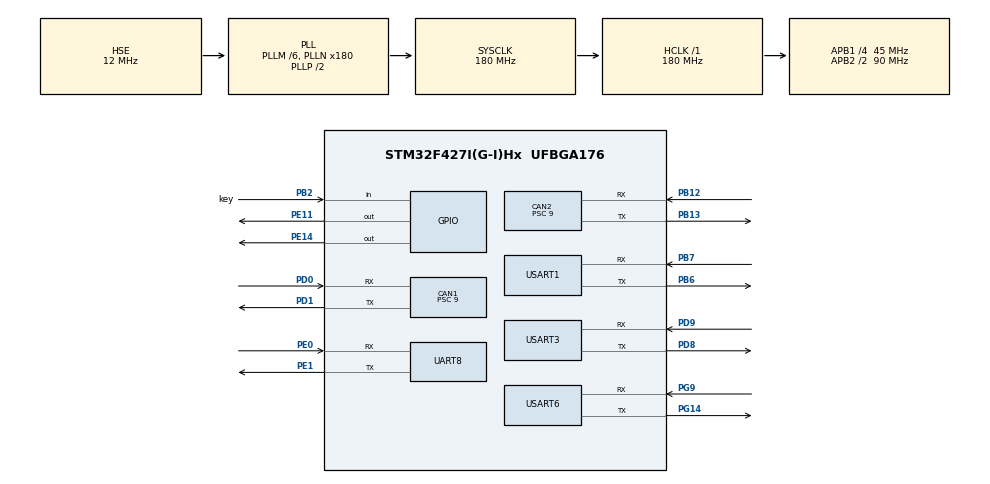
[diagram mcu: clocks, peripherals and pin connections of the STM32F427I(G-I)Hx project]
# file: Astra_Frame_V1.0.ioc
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CAN1.BS1=CAN_BS1_2TQ
CAN1.BS2=CAN_BS2_2TQ
CAN1.CalculateBaudRate=1000000
CAN1.CalculateTimeBit=1000
CAN1.CalculateTimeQuantum=200.0
CAN1.Prescaler=9
CAN2.BS1=CAN_BS1_2TQ
CAN2.BS2=CAN_BS2_2TQ
CAN2.CalculateBaudRate=1000000
CAN2.CalculateTimeBit=1000
CAN2.CalculateTimeQuantum=200.0
CAN2.Prescaler=9
Dma.Request0=USART1_RX
Dma.Request1=USART1_TX
Dma.Request2=USART3_RX
Dma.Request3=USART6_TX
Dma.Request4=USART6_RX
Dma.Request5=UART8_RX
Dma.Request6=UART8_TX
Dma.UART8_RX.5.Direction=DMA_PERIPH_TO_MEMORY
Dma.UART8_RX.5.FIFOMode=DMA_FIFOMODE_DISABLE
Dma.UART8_RX.5.Instance=DMA1_Stream6
Dma.UART8_RX.5.MemDataAlignment=DMA_MDATAALIGN_BYTE
Dma.UART8_RX.5.MemInc=DMA_MINC_ENABLE
Dma.UART8_RX.5.Mode=DMA_NORMAL
Dma.UART8_RX.5.PeriphDataAlignment=DMA_PDATAALIGN_BYTE
Dma.UART8_RX.5.PeriphInc=DMA_PINC_DISABLE
Dma.UART8_RX.5.Priority=DMA_PRIORITY_LOW
Dma.UART8_TX.6.Direction=DMA_MEMORY_TO_PERIPH
Dma.UART8_TX.6.FIFOMode=DMA_FIFOMODE_DISABLE
Dma.UART8_TX.6.Instance=DMA1_Stream0
Dma.UART8_TX.6.MemDataAlignment=DMA_MDATAALIGN_BYTE
Dma.UART8_TX.6.MemInc=DMA_MINC_ENABLE
Dma.UART8_TX.6.Mode=DMA_NORMAL
Dma.UART8_TX.6.PeriphDataAlignment=DMA_PDATAALIGN_BYTE
Dma.UART8_TX.6.PeriphInc=DMA_PINC_DISABLE
Dma.UART8_TX.6.Priority=DMA_PRIORITY_LOW
Dma.USART1_RX.0.Direction=DMA_PERIPH_TO_MEMORY
Dma.USART1_RX.0.FIFOMode=DMA_FIFOMODE_DISABLE
Dma.USART1_RX.0.Instance=DMA2_Stream2
Dma.USART1_RX.0.MemDataAlignment=DMA_MDATAALIGN_BYTE
Dma.USART1_RX.0.MemInc=DMA_MINC_ENABLE
Dma.USART1_RX.0.Mode=DMA_NORMAL
Dma.USART1_RX.0.PeriphDataAlignment=DMA_PDATAALIGN_BYTE
Dma.USART1_RX.0.PeriphInc=DMA_PINC_DISABLE
Dma.USART1_RX.0.Priority=DMA_PRIORITY_LOW
Dma.USART1_TX.1.Direction=DMA_MEMORY_TO_PERIPH
Dma.USART1_TX.1.FIFOMode=DMA_FIFOMODE_DISABLE
Dma.USART1_TX.1.Instance=DMA2_Stream7
Dma.USART1_TX.1.MemDataAlignment=DMA_MDATAALIGN_BYTE
Dma.USART1_TX.1.MemInc=DMA_MINC_ENABLE
Dma.USART1_TX.1.Mode=DMA_NORMAL
Dma.USART1_TX.1.PeriphDataAlignment=DMA_PDATAALIGN_BYTE
Dma.USART1_TX.1.PeriphInc=DMA_PINC_DISABLE
Dma.USART1_TX.1.Priority=DMA_PRIORITY_LOW
Dma.USART3_RX.2.Direction=DMA_PERIPH_TO_MEMORY
Dma.USART3_RX.2.FIFOMode=DMA_FIFOMODE_DISABLE
Dma.USART3_RX.2.Instance=DMA1_Stream1
Dma.USART3_RX.2.MemDataAlignment=DMA_MDATAALIGN_BYTE
Dma.USART3_RX.2.MemInc=DMA_MINC_ENABLE
Dma.USART3_RX.2.Mode=DMA_NORMAL
Dma.USART3_RX.2.PeriphDataAlignment=DMA_PDATAALIGN_BYTE
Dma.USART3_RX.2.PeriphInc=DMA_PINC_DISABLE
Dma.USART3_RX.2.Priority=DMA_PRIORITY_LOW
Dma.USART6_RX.4.Direction=DMA_PERIPH_TO_MEMORY
Dma.USART6_RX.4.FIFOMode=DMA_FIFOMODE_DISABLE
Dma.USART6_RX.4.Instance=DMA2_Stream1
Dma.USART6_RX.4.MemDataAlignment=DMA_MDATAALIGN_BYTE
Dma.USART6_RX.4.MemInc=DMA_MINC_ENABLE
Dma.USART6_RX.4.Mode=DMA_NORMAL
Dma.USART6_RX.4.PeriphDataAlignment=DMA_PDATAALIGN_BYTE
Dma.USART6_RX.4.PeriphInc=DMA_PINC_DISABLE
Dma.USART6_RX.4.Priority=DMA_PRIORITY_LOW
Dma.USART6_TX.3.Direction=DMA_MEMORY_TO_PERIPH
Dma.USART6_TX.3.FIFOMode=DMA_FIFOMODE_DISABLE
Dma.USART6_TX.3.Instance=DMA2_Stream6
Dma.USART6_TX.3.MemDataAlignment=DMA_MDATAALIGN_BYTE
Dma.USART6_TX.3.MemInc=DMA_MINC_ENABLE
Dma.USART6_TX.3.Mode=DMA_NORMAL
Dma.USART6_TX.3.PeriphDataAlignment=DMA_PDATAALIGN_BYTE
Dma.USART6_TX.3.PeriphInc=DMA_PINC_DISABLE
Dma.USART6_TX.3.Priority=DMA_PRIORITY_LOW
FREERTOS.INCLUDE_eTaskGetState=1
FREERTOS.INCLUDE_pcTaskGetTaskName=1
FREERTOS.INCLUDE_uxTaskGetStackHighWaterMark=1
FREERTOS.INCLUDE_uxTaskGetStackHighWaterMark2=1
FREERTOS.INCLUDE_vTaskCleanUpResources=1
FREERTOS.INCLUDE_vTaskDelayUntil=1
FREERTOS.INCLUDE_xQueueGetMutexHolder=1
FREERTOS.INCLUDE_xSemaphoreGetMutexHolder=1
FREERTOS.INCLUDE_xTaskAbortDelay=1
FREERTOS.INCLUDE_xTaskGetCurrentTaskHandle=1
FREERTOS.INCLUDE_xTaskGetHandle=1
FREERTOS.Tasks01=defaultTask,0,256,StartDefaultTask,Default,NULL,Dynamic,NULL,NULL;Gimbal,1,512,Gimbal_Task,As weak,NULL,Dynamic,NULL,NULL;Referee,0,512,Referee_Task,As weak,NULL,Dynamic,NULL,NULL;Chassis,1,512,Chassis_Task,As weak,NULL,Dynamic,NULL,NULL;Data,1,512,Data_Task,As weak,NULL,Dynamic,NULL,NULL;AmmoBooster,1,512,AmmoBooster_Task,As weak,NULL,Dynamic,NULL,NULL;Status,0,512,Status_Task,As weak,NULL,Dynamic,NULL,NULL
Mcu.Family=STM32F4
Mcu.Name=STM32F427I(G-I)Hx
Mcu.Package=UFBGA176
NVIC.CAN1_RX0_IRQn=true\:5\:0\:false\:false\:true\:true\:true\:true\:true
NVIC.CAN2_RX0_IRQn=true\:5\:0\:false\:false\:true\:true\:true\:true\:true
NVIC.DMA1_Stream0_IRQn=true\:5\:0\:false\:false\:true\:true\:false\:true\:true
NVIC.DMA1_Stream1_IRQn=true\:5\:0\:true\:false\:true\:true\:false\:true\:true
NVIC.DMA1_Stream6_IRQn=true\:5\:0\:false\:false\:true\:true\:false\:true\:true
NVIC.DMA2_Stream1_IRQn=true\:5\:0\:false\:false\:true\:true\:false\:true\:true
NVIC.DMA2_Stream2_IRQn=true\:5\:0\:false\:false\:true\:true\:false\:true\:true
NVIC.DMA2_Stream6_IRQn=true\:5\:0\:false\:false\:true\:true\:false\:true\:true
NVIC.DMA2_Stream7_IRQn=true\:5\:0\:false\:false\:true\:true\:false\:true\:true
NVIC.FPU_IRQn=true\:5\:0\:false\:false\:true\:true\:true\:false\:true
NVIC.PriorityGroup=NVIC_PRIORITYGROUP_4
NVIC.UART8_IRQn=true\:5\:0\:false\:false\:true\:true\:true\:true\:true
NVIC.USART1_IRQn=true\:5\:0\:false\:false\:true\:true\:true\:true\:true
NVIC.USART3_IRQn=true\:5\:0\:false\:false\:true\:true\:true\:true\:true
NVIC.USART6_IRQn=true\:5\:0\:false\:false\:true\:true\:true\:true\:true
PA13.Mode=Serial_Wire
PA13.Signal=SYS_JTMS-SWDIO
PA14.Mode=Serial_Wire
PA14.Signal=SYS_JTCK-SWCLK
PB12.Mode=CAN_Activate
PB12.Signal=CAN2_RX
PB13.Mode=CAN_Activate
PB13.Signal=CAN2_TX
PB2/BOOT1.GPIO_Label=key
PB2/BOOT1.Signal=GPIO_Input
PB6.Mode=Asynchronous
PB6.Signal=USART1_TX
PB7.Mode=Asynchronous
PB7.Signal=USART1_RX
PC14/OSC32_IN.Mode=LSE-External-Oscillator
PC14/OSC32_IN.Signal=RCC_OSC32_IN
PC15/OSC32_OUT.Mode=LSE-External-Oscillator
PC15/OSC32_OUT.Signal=RCC_OSC32_OUT
PD0.Mode=CAN_Activate
PD0.Signal=CAN1_RX
PD1.Mode=CAN_Activate
PD1.Signal=CAN1_TX
PD8.Mode=Asynchronous
PD8.Signal=USART3_TX
PD9.Mode=Asynchronous
PD9.Signal=USART3_RX
PE0.Mode=Asynchronous
PE0.Signal=UART8_RX
PE1.Mode=Asynchronous
PE1.Signal=UART8_TX
PE11.Signal=GPIO_Output
PE14.Signal=GPIO_Output
PG14.Mode=Asynchronous
PG14.Signal=USART6_TX
PG9.Mode=Asynchronous
PG9.Signal=USART6_RX
PH0/OSC_IN.Mode=HSE-External-Oscillator
PH0/OSC_IN.Signal=RCC_OSC_IN
PH1/OSC_OUT.Mode=HSE-External-Oscillator
PH1/OSC_OUT.Signal=RCC_OSC_OUT
ProjectManager.HeapSize=0x200
ProjectManager.StackSize=0x400
ProjectManager.TargetToolchain=CMake
RCC.48MHZClocksFreq_Value=90000000
RCC.AHBFreq_Value=180000000
RCC.APB1CLKDivider=RCC_HCLK_DIV4
RCC.APB1Freq_Value=45000000
RCC.APB1TimFreq_Value=90000000
RCC.APB2CLKDivider=RCC_HCLK_DIV2
RCC.APB2Freq_Value=90000000
RCC.APB2TimFreq_Value=180000000
RCC.CortexFreq_Value=180000000
RCC.HCLKFreq_Value=180000000
RCC.HSE_VALUE=12000000
RCC.HSI_VALUE=16000000
RCC.PLLM=6
RCC.PLLN=180
RCC.PLLSourceVirtual=RCC_PLLSOURCE_HSE
RCC.SYSCLKFreq_VALUE=180000000
RCC.SYSCLKSource=RCC_SYSCLKSOURCE_PLLCLK
RCC.VCOOutputFreq_Value=360000000
UART8.VirtualMode=Asynchronous
USART1.VirtualMode=VM_ASYNC
USART3.VirtualMode=VM_ASYNC
USART6.VirtualMode=VM_ASYNC
VP_FREERTOS_VS_CMSIS_V1.Mode=CMSIS_V1
board=custom

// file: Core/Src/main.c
/* USER CODE BEGIN Header */
/**
  ******************************************************************************
  * @file           : main.c
  * @brief          : Main program body
  ******************************************************************************
  * @attention
  *
  * Copyright (c) 2026 STMicroelectronics.
  * All rights reserved.
  *
  * This software is licensed under terms that can be found in the LICENSE file
  * in the root directory of this software component.
  * If no LICENSE file comes with this software, it is provided AS-IS.
  *
  ******************************************************************************
  */
/* USER CODE END Header */
#include "main.h"
#include "cmsis_os.h"
#include "can.h"
#include "dma.h"
#include "usart.h"
#include "gpio.h"
#include "Data.h"
#include "bsp_can.h"
#include "remote_control.h"
#include "referee.h"

void SystemClock_Config(void);
void MX_FREERTOS_Init(void);

int main(void)
{

  /* MCU Configuration--------------------------------------------------------*/

  /* Reset of all peripherals, Initializes the Flash interface and the Systick. */
  HAL_Init();

  /* Configure the system clock */
  SystemClock_Config();

  /* Initialize all configured peripherals */
  MX_GPIO_Init();
  MX_DMA_Init();
  MX_CAN1_Init();
  MX_CAN2_Init();
  MX_USART1_UART_Init();
  MX_USART3_UART_Init();
  MX_USART6_UART_Init();
  MX_UART8_Init();
  /* USER CODE BEGIN 2 */
  can_filter_init();
  remote_control_init();
  referee_system_init();
  Chassis_PID_Init();

  /* USER CODE END 2 */

  /* Call init function for freertos objects (in cmsis_os2.c) */
  MX_FREERTOS_Init();

  /* Start scheduler */
  osKernelStart();

  /* We should never get here as control is now taken by the scheduler */

  /* Infinite loop */
  while (1)
  {

  }
}

void SystemClock_Config(void)
{
  RCC_OscInitTypeDef RCC_OscInitStruct = {0};
  RCC_ClkInitTypeDef RCC_ClkInitStruct = {0};

  /** Configure the main internal regulator output voltage
  */
  __HAL_RCC_PWR_CLK_ENABLE();
  __HAL_PWR_VOLTAGESCALING_CONFIG(PWR_REGULATOR_VOLTAGE_SCALE1);

  /** Initializes the RCC Oscillators according to the specified parameters
  * in the RCC_OscInitTypeDef structure.
  */
  RCC_OscInitStruct.OscillatorType = RCC_OSCILLATORTYPE_HSE;
  RCC_OscInitStruct.HSEState = RCC_HSE_ON;
  RCC_OscInitStruct.PLL.PLLState = RCC_PLL_ON;
  RCC_OscInitStruct.PLL.PLLSource = RCC_PLLSOURCE_HSE;
  RCC_OscInitStruct.PLL.PLLM = 6;
  RCC_OscInitStruct.PLL.PLLN = 180;
  RCC_OscInitStruct.PLL.PLLP = RCC_PLLP_DIV2;
  RCC_OscInitStruct.PLL.PLLQ = 4;
  if (HAL_RCC_OscConfig(&RCC_OscInitStruct) != HAL_OK)
  {
    Error_Handler();
  }

  /** Activate the Over-Drive mode
  */
  if (HAL_PWREx_EnableOverDrive() != HAL_OK)
  {
    Error_Handler();
  }

  /** Initializes the CPU, AHB and APB buses clocks
  */
  RCC_ClkInitStruct.ClockType = RCC_CLOCKTYPE_HCLK|RCC_CLOCKTYPE_SYSCLK
                              |RCC_CLOCKTYPE_PCLK1|RCC_CLOCKTYPE_PCLK2;
  RCC_ClkInitStruct.SYSCLKSource = RCC_SYSCLKSOURCE_PLLCLK;
  RCC_ClkInitStruct.AHBCLKDivider = RCC_SYSCLK_DIV1;
  RCC_ClkInitStruct.APB1CLKDivider = RCC_HCLK_DIV4;
  RCC_ClkInitStruct.APB2CLKDivider = RCC_HCLK_DIV2;

  if (HAL_RCC_ClockConfig(&RCC_ClkInitStruct, FLASH_LATENCY_5) != HAL_OK)
  {
    Error_Handler();
  }
}

void Error_Handler(void)
{
  __disable_irq();
  while (1)
  {
  }
}

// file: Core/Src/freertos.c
/* USER CODE BEGIN Header */
/**
  ******************************************************************************
  * File Name          : freertos.c
  * Description        : Code for freertos applications
  ******************************************************************************
  * @attention
  *
  * Copyright (c) 2026 STMicroelectronics.
  * All rights reserved.
  *
  * This software is licensed under terms that can be found in the LICENSE file
  * in the root directory of this software component.
  * If no LICENSE file comes with this software, it is provided AS-IS.
  *
  ******************************************************************************
  */
/* USER CODE END Header */

#include "FreeRTOS.h"
#include "task.h"
#include "main.h"
#include "cmsis_os.h"

osThreadId defaultTaskHandle;
osThreadId GimbalHandle;
osThreadId RefereeHandle;
osThreadId ChassisHandle;
osThreadId DataHandle;
osThreadId AmmoBoosterHandle;
osThreadId StatusHandle;

void StartDefaultTask(void const * argument);
void Gimbal_Task(void const * argument);
void Referee_Task(void const * argument);
void Chassis_Task(void const * argument);
void Data_Task(void const * argument);
void AmmoBooster_Task(void const * argument);
void Status_Task(void const * argument);

void MX_FREERTOS_Init(void); /* (MISRA C 2004 rule 8.1) */

/* GetIdleTaskMemory prototype (linked to static allocation support) */
void vApplicationGetIdleTaskMemory( StaticTask_t **ppxIdleTaskTCBBuffer, StackType_t **ppxIdleTaskStackBuffer, uint32_t *pulIdleTaskStackSize );

/* USER CODE BEGIN GET_IDLE_TASK_MEMORY */
static StaticTask_t xIdleTaskTCBBuffer;
static StackType_t xIdleStack[configMINIMAL_STACK_SIZE];

void vApplicationGetIdleTaskMemory( StaticTask_t **ppxIdleTaskTCBBuffer, StackType_t **ppxIdleTaskStackBuffer, uint32_t *pulIdleTaskStackSize )
{
  *ppxIdleTaskTCBBuffer = &xIdleTaskTCBBuffer;
  *ppxIdleTaskStackBuffer = &xIdleStack[0];
  *pulIdleTaskStackSize = configMINIMAL_STACK_SIZE;
  /* place for user code */
}
/* USER CODE END GET_IDLE_TASK_MEMORY */

void MX_FREERTOS_Init(void) {

  /* Create the thread(s) */
  /* definition and creation of defaultTask */
  osThreadDef(defaultTask, StartDefaultTask, osPriorityNormal, 0, 256);
  defaultTaskHandle = osThreadCreate(osThread(defaultTask), NULL);

  /* definition and creation of Gimbal */
  osThreadDef(Gimbal, Gimbal_Task, osPriorityAboveNormal, 0, 512);
  GimbalHandle = osThreadCreate(osThread(Gimbal), NULL);

  /* definition and creation of Referee */
  osThreadDef(Referee, Referee_Task, osPriorityNormal, 0, 512);
  RefereeHandle = osThreadCreate(osThread(Referee), NULL);

  /* definition and creation of Chassis */
  osThreadDef(Chassis, Chassis_Task, osPriorityAboveNormal, 0, 512);
  ChassisHandle = osThreadCreate(osThread(Chassis), NULL);

  /* definition and creation of Data */
  osThreadDef(Data, Data_Task, osPriorityAboveNormal, 0, 512);
  DataHandle = osThreadCreate(osThread(Data), NULL);

  /* definition and creation of AmmoBooster */
  osThreadDef(AmmoBooster, AmmoBooster_Task, osPriorityAboveNormal, 0, 512);
  AmmoBoosterHandle = osThreadCreate(osThread(AmmoBooster), NULL);

  /* definition and creation of Status */
  osThreadDef(Status, Status_Task, osPriorityNormal, 0, 512);
  StatusHandle = osThreadCreate(osThread(Status), NULL);

}

void StartDefaultTask(void const * argument)
{
  for(;;)
  {
    osDelay(1);
  }
}

__weak void Gimbal_Task(void const * argument)
{
  for(;;)
  {
    osDelay(1);
  }
}

__weak void Referee_Task(void const * argument)
{
  for(;;)
  {
    osDelay(1);
  }
}

__weak void Chassis_Task(void const * argument)
{
  for(;;)
  {
    osDelay(1);
  }
}

__weak void Data_Task(void const * argument)
{
  for(;;)
  {
    osDelay(1);
  }
}

__weak void AmmoBooster_Task(void const * argument)
{
  for(;;)
  {
    osDelay(1);
  }
}

__weak void Status_Task(void const * argument)
{
  for(;;)
  {
    osDelay(1);
  }
}
